# NUC100BN_v1 register map
File version: 1.0
Registers are 32-bit, read-write, reset 0x0 unless marked. A register's access mark holds for its fields unless they carry their own. Offsets are from the block's base; [hi:lo] are bit positions.

## CMP — CMP Register Map
Base 0x400D0000
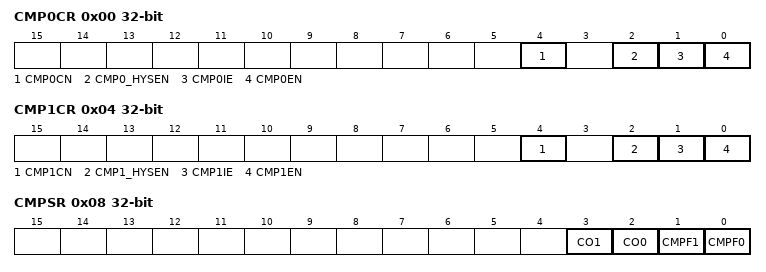
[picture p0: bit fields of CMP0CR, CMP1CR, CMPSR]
0x00 CMP0CR — Comparator0 Control Register
  [4] CMP0CN — Comparator0 Negative Input Selection
    0=The source of the negative comparator input is from CPN0 pin; 1=Internal band-gap reference voltage is selected as the source of negative comparator input
  [2] CMP0_HYSEN — Comparator0 Hysteresis Enable
    0=Hysteresis function Disabled (Default); 1=Hysteresis function Enabled. The typical range is 20mV
  [1] CMP0IE — Comparator0 Interrupt Enable
    0=Interrupt function Disabled; 1=Interrupt function Enabled
  [0] CMP0EN — Comparator0 Enable. Comparator output needs wait 2 us stable time after CMP0EN is set.
    0=Disabled; 1=Enabled
0x04 CMP1CR — Comparator1 Control Register
  [4] CMP1CN — Comparator1 Negative Input Selection
    0=The source of the negative comparator input is from CPN1 pin; 1=Internal band-gap reference voltage is selected as the source of negative comparator input
  [2] CMP1_HYSEN — Comparator1 Hysteresis Enable
    0=Hysteresis function Disabled (default); 1=Hysteresis function Enabled. The typical range is 20mV
  [1] CMP1IE — Comparator1 Interrupt Enable
    0=Interrupt function Disabled; 1=Interrupt function Enabled
  [0] CMP1EN — Comparator1 Enable. Comparator output needs to wait 2 us stable time after CMP1EN is set.
    0=Disabled; 1=Enabled
0x08 CMPSR — Comparator Status Register
  [3] CO1 — Comparator1 Output
  [2] CO0 — Comparator0 Output
  [1] CMPF1 — Comparator1 Flag. This bit is set by hardware whenever the comparator1 output changes state. This will cause an interrupt if CMP1IE set. Write 1 to clear this bit to 0.
  [0] CMPF0 — Comparator0 Flag. This bit is set by hardware whenever the comparator0 output changes state. This will cause an interrupt if CMP0IE set. Write 1 to clear this bit to 0.

## EBI — EBI Register Map
Base 0x50010000
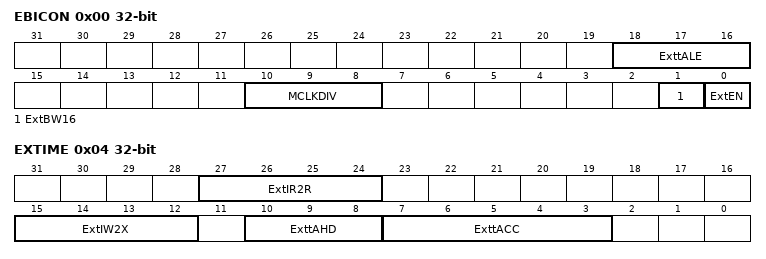
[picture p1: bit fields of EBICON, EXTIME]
0x00 EBICON — External Bus Interface General Control Register
  [18:16] ExttALE — Expand Time of ALE. The ALE width (tALE) to latch the address can be controlled by ExttALE.
  [10:8] MCLKDIV — External Output Clock Divider
  [1] ExtBW16 — EBI Data Width 16-bit. This bit defines if the data bus is 8-bit or 16-bit.
    0=EBI data width is 8-bit; 1=EBI data width is 16-bit
  [0] ExtEN — EBI Enable. This bit is the functional enable bit for EBI.
    0=EBI function Disabled; 1=EBI function Enabled
0x04 EXTIME — External Bus Interface Timing Control Register
  [27:24] ExtIR2R — Idle State Cycle Between Read-Read. When read action is finished and the next action is going to read, idle state is inserted and nCS return to high if ExtIR2R is not zero.
  [15:12] ExtIW2X — Idle State Cycle After Write. When write action is finished, idle state is inserted and nCS return to high if ExtIW2X is not zero.
  [10:8] ExttAHD — EBI Data Access Hold Time. ExttAHD defines data access hold time (tAHD).
  [7:3] ExttACC — EBI Data Access Time. ExttACC defines data access time (tACC).

## FMC — FMC Register Map
Base 0x5000C000
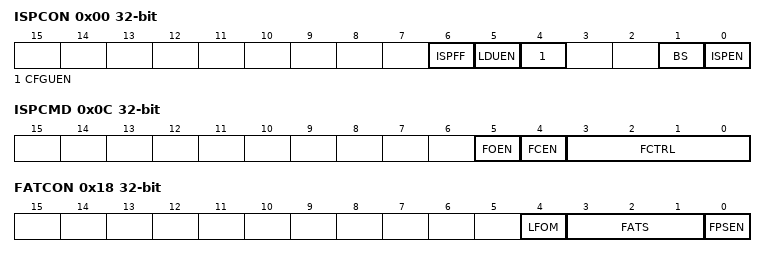
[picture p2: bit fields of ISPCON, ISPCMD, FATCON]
0x00 ISPCON — ISP Control Register
  [6] ISPFF — ISP Fail Flag (Write-protection Bit). This bit is set by hardware when a triggered ISP meets any of the following conditions: (1) APROM writes to itself (2) LDROM writes to itself (3) CONFIG is erased/programmed if CFGUEN is set to 0 (4) Destination address is illegal, such as over an available range. Write 1 to clear.
  [5] LDUEN — LDROM Update Enable (Write-protection Bit)
    0=LDROM cannot be updated; 1=LDROM can be updated when the chip runs in APROM
  [4] CFGUEN — Enable Config-bits Update by ISP (Write-protection Bit)
    0=ISP Disabled for config-bits update; 1=ISP Enabled for config-bits update
  [1] BS — Boot Selection (Write-protection Bit). Set/clear this bit to select next booting from LDROM/APROM, respectively. This bit also functions as chip booting status flag, which can be used to check where chip booted from. This bit is initiated with the inversed value of CBS in Config0 after any reset is happened except CPU reset (RSTS_CPU is 1) or system reset (RSTS_SYS) is happened
    0=Boot from APROM; 1=Boot from LDROM
  [0] ISPEN — ISP Enable (Write-protection Bit). ISP function enable bit. Set this bit to enable ISP function.
    0=ISP function Disabled; 1=ISP function Enabled
0x04 ISPADR — ISP Address Register
  [31:0] ISPADR — ISP Address. The NuMicro( NUC100 Series has a maximum of 32Kx32 embedded flash; it supports word program only. ISPADR[1:0] must be kept 00b for ISP operation.
0x08 ISPDAT — ISP Data Register
  [31:0] ISPDAT — ISP Data. Write data to this register before ISP program operation. Read data from this register after ISP read operation.
0x0C ISPCMD — ISP Command Register
  [5] FOEN — ISP Command
  [4] FCEN — ISP Command
  [3:0] FCTRL — ISP Command
0x10 ISPTRG — ISP Trigger Register
  [0] ISPGO — ISP start trigger (Write-protection Bit). Write 1 to start ISP operation and this bit will be cleared to 0 by hardware automatically when ISP operation is finished. This bit is the protected bit, It means programming this bit needs to write "59h", "16h", "88h" to address 0x5000_0100 to disable register protection. Refer to the register REGWRPROT at address GCR_BA+0x100.
    0=ISP operation finished; 1=ISP progressed
0x14 DFBADR ro reset 0x1F000 — Data Flash Start Address (AP ROM Size Is Less Than 128KB)
  [31:0] DFBADR — Data Flash Base Address. This register indicates data flash start address. It is read only. For 128KB flash memory device, the data flash size is defined by user configuration, register content is loaded from Config1 when chip power on but for 64/32KB device, it is fixed at 0x0001_F000.
0x18 FATCON — Flash Access Window Control Register
  [4] LFOM — Low Frequency Optimization Mode (Write-protection Bit). When chip operation frequency is lower than 25 MHz, chip can work more efficiently by setting this bit to 1 (This bit is only for NuMicro( NUC100/NUC120 Low Density.)
    0=Low frequency optimization mode Disabled; 1=Low frequency optimization mode Enabled
  [3:1] FATS — Flash Access Time Window Selection (Write-protection Bits)
  [0] FPSEN — Flash Power Save Enable (Write-protection Bit). If CPU clock is slower than 24 MHz, software can enable flash power saving function.
    0=Flash power saving Disabled; 1=Flash power saving Enabled
